# M030GAE register map
File version: 1.0
Registers are 32-bit, read-write, reset 0x0 unless marked. A register's access mark holds for its fields unless they carry their own. Offsets are from the block's base; [hi:lo] are bit positions; 'fields as' and 'values as' point back to an identical list.

## CLK — CLK Register Map
Base 0x40000200
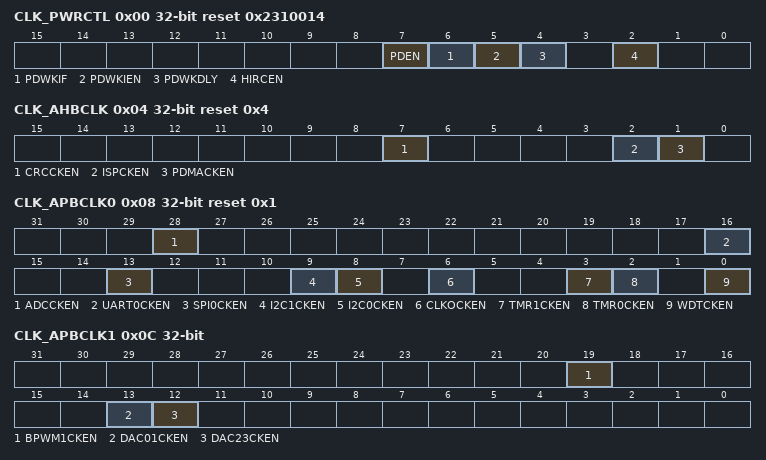
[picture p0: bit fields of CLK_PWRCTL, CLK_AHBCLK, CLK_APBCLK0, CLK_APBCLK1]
0x00 CLK_PWRCTL reset 0x2310014 — System Power-down Control Register
  [7] PDEN — System Power-down Enable (Write Protect). When this bit is set to 1, Power-down mode is enabled and chip keeps active till the CPU sleep mode is also active and then the chip enters Power-down mode. When chip wakes up from Power-down mode, this bit is auto cleared. Users need to set this bit again for next Power-down. In Power-down mode, the HIRC will be disabled in this mode, but LIRC are not controlled by Power-down mode. If user disable LIRC before entering power-down mode, this bit should be set after LIRC disabled at least 50us. The clocks of peripheral are not controlled by Power-down mode, if the peripheral clock source is from LIRC. Note: This bit is write protected. Refer to the SYS_REGLCTL register.
    0=Chip operating normally or chip in idle mode because of WFI command; 1=Chip enters Power-down mode instantly or waits CPU sleep command WFI
  [6] PDWKIF — Power-down Mode Wake-up Interrupt Status. Set by 'Power-down wake-up event', it indicates that resume from Power-down mode' The flag is set if any wake-up source is occurred. Refer Power Modes and Wake-up Sources chapter. Note 1: Write 1 to clear the bit to 0. Note 2: This bit works only if PDWKIEN (CLK_PWRCTL[5]) set to 1.
  [5] PDWKIEN — Power-down Mode Wake-up Interrupt Enable Bit (Write Protect). Note 1: The interrupt will occur when both PDWKIF and PDWKIEN are high. Note 2: This bit is write protected. Refer to the SYS_REGLCTL register.
    0=Power-down mode wake-up interrupt Disabled; 1=Power-down mode wake-up interrupt Enabled
  [4] PDWKDLY — Enable the Wake-up Delay Counter (Write Protect). When the chip wakes up from Power-down mode, the clock control will delay certain clock cycles to wait system clock stable. The delayed clock cycle is 512 clock cycles when chip works at internal high speed RC oscillator (HIRC). Note: This bit is write protected. Refer to the SYS_REGLCTL register.
    0=Clock cycles delay Disabled; 1=Clock cycles delay Enabled
  [2] HIRCEN — HIRC Enable Bit (Write Protect). Note: This bit is write protected. Refer to the SYS_REGLCTL register.
    0=Internal high speed RC oscillator (HIRC) Disabled; 1=Internal high speed RC oscillator (HIRC) Enabled
0x04 CLK_AHBCLK reset 0x4 — AHB Devices Clock Enable Control Register
  [7] CRCCKEN — CRC Generator Controller Clock Enable Bit
    0=CRC peripheral clock Disabled; 1=CRC peripheral clock Enabled
  [2] ISPCKEN — Flash ISP Controller Clock Enable Bit
    0=Flash ISP peripheral clock Disabled; 1=Flash ISP peripheral clock Enabled
  [1] PDMACKEN — PDMA Controller Clock Enable Bit
    0=PDMA peripheral clock Disabled; 1=PDMA peripheral clock Enabled
0x08 CLK_APBCLK0 reset 0x1 — APB Devices Clock Enable Control Register 0
  [28] ADCCKEN — ADC Clock Enable Bit
    0=ADC clock Disabled; 1=ADC clock Enabled
  [16] UART0CKEN — UART0 Clock Enable Bit
    0=UART0 clock Disabled; 1=UART0 clock Enabled
  [13] SPI0CKEN — SPI0 Clock Enable Bit
    0=SPI0 clock Disabled; 1=SPI0 clock Enabled
  [9] I2C1CKEN — I2C1 Clock Enable Bit
    0=I2C1 clock Disabled; 1=I2C1 clock Enabled
  [8] I2C0CKEN — I2C0 Clock Enable Bit
    0=I2C0 clock Disabled; 1=I2C0 clock Enabled
  [6] CLKOCKEN — CLKO Clock Enable Bit
    0=CLKO clock Disabled; 1=CLKO clock Enabled
  [3] TMR1CKEN — Timer1 Clock Enable Bit
    0=Timer1 clock Disabled; 1=Timer1 clock Enabled
  [2] TMR0CKEN — Timer0 Clock Enable Bit
    0=Timer0 clock Disabled; 1=Timer0 clock Enabled
  [0] WDTCKEN — Watchdog Timer Clock Enable Bit (Write Protect). Note 1: This bit is write protected. Refer to the SYS_REGLCTL register. Note 2: This bit is reset by power on reset, Watchdog reset or software chip reset.
    0=Watchdog timer clock Disabled; 1=Watchdog timer clock Enabled
0x0C CLK_APBCLK1 — APB Devices Clock Enable Control Register 1
  [19] BPWM1CKEN — BPWM1 Clock Enable Bit
    0=BPWM1 clock Disabled; 1=BPWM1 clock Enabled
  [13] DAC01CKEN — DAC01 Clock Enable Bit
    0=DAC01 clock Disabled; 1=DAC01 clock Enabled
  [12] DAC23CKEN — DAC23 Clock Enable Bit
    0=DAC23 clock Disabled; 1=DAC23 clock Enabled
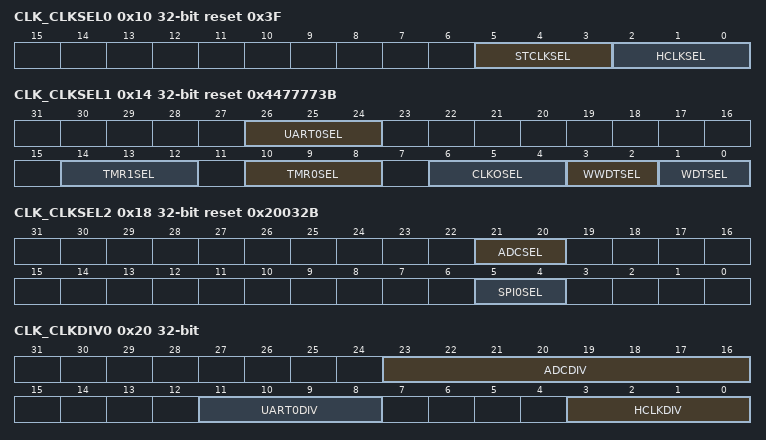
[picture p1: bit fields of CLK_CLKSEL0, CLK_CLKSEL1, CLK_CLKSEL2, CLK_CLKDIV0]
0x10 CLK_CLKSEL0 reset 0x3F — Clock Source Select Control Register 0
  [5:3] STCLKSEL — Cortex-M0 SysTick Clock Source Selection (Write Protect). Note 2: This bit is write protected. Refer to the SYS_REGLCTL register.
    3=Clock source from HCLK/2; 7=Clock source from HIRC/2
  [2:0] HCLKSEL — HCLK Clock Source Selection (Write Protect). Before clock switching, the related clock sources (both pre-select and new-select) must be turned on. Note 1: This bit is write protected. Refer to the SYS_REGLCTL register. Note 2: Reset by power on reset
    7=Clock source from HIRC
0x14 CLK_CLKSEL1 reset 0x4477773B — Clock Source Select Control Register 1
  [26:24] UART0SEL — UART0 Clock Source Selection
    3=Clock source from internal high speed RC oscillator (HIRC); 4=Clock source from PCLK0; 5=Clock source from internal low speed RC oscillator (LIRC)
  [14:12] TMR1SEL — TIMER1 Clock Source Selection
    2=Clock source from PCLK0; 3=Clock source from external clock T1 pin; 5=Clock source from internal low speed RC oscillator (LIRC); 7=Clock source from internal high speed RC oscillator (HIRC)
  [10:8] TMR0SEL — TIMER0 Clock Source Selection
    2=Clock source from PCLK0; 3=Clock source from external clock T0 pin; 5=Clock source from internal low speed RC oscillator (LIRC); 7=Clock source from internal high speed RC oscillator (HIRC)
  [6:4] CLKOSEL — Clock Divider Clock Source Selection
    2=Clock source from HCLK; 3=Clock source from internal high speed RC oscillator (HIRC); 4=Clock source from internal low speed RC oscillator (LIRC); 5=Clock source from internal high speed RC oscillator (HIRC)
  [3:2] WWDTSEL — Window Watchdog Timer Clock Source Selection (Write Protect)
    2=Clock source from HCLK/2048; 3=Clock source from internal low speed RC oscillator (LIRC)
  [1:0] WDTSEL — Watchdog Timer Clock Source Selection (Write Protect). Note1: This bit is write protected. Refer to the SYS_REGLCTL registere. Note2: This bit is force to 11 when CONFIG0[31], CONFIG0[4], CONFIG0[3] are all ones.
    values as WWDTSEL
0x18 CLK_CLKSEL2 reset 0x20032B — Clock Source Select Control Register 2
  [21:20] ADCSEL — ADC Clock Source Selection
    2=Clock source from PCLK1; 3=Clock source from internal high speed RC oscillator (HIRC) clock
  [5:4] SPI0SEL — SPI0 Clock Source Selection
    2=Clock source from PCLK1; 3=Clock source from internal high speed RC oscillator (HIRC)
0x20 CLK_CLKDIV0 — Clock Divider Number Register 0
  [23:16] ADCDIV — ADC Clock Divide Number From ADC Clock Source
  [11:8] UART0DIV — UART0 Clock Divide Number From UART0 Clock Source
  [3:0] HCLKDIV — HCLK Clock Divide Number From HCLK Clock Source
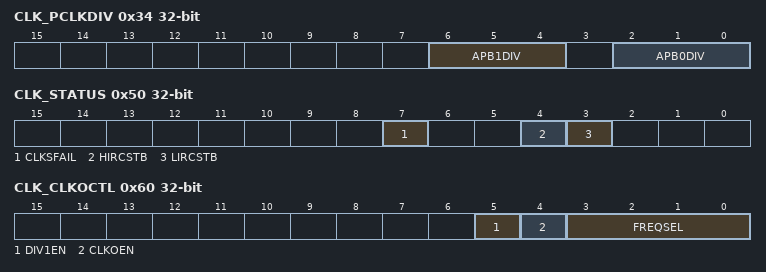
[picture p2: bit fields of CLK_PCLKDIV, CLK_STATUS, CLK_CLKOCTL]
0x34 CLK_PCLKDIV — APB Clock Divider Register
  [6:4] APB1DIV — APB1 Clock DIvider. APB1 clock can be divided from HCLK. Others: Reserved.
  [2:0] APB0DIV — APB0 Clock DIvider. APB0 clock can be divided from HCLK. Others: Reserved.
0x50 CLK_STATUS ro (reset mask 0xFFFFFF00) — Clock Status Monitor Register
  [7] CLKSFAIL — Clock Switching Fail Flag (Read Only). This bit is updated when software switches system clock source. If switch target clock is stable, this bit will be set to 0. If switch target clock is not stable, this bit will be set to 1. Note: Write 1 to clear the bit to 0.
    0=Clock switching success; 1=Clock switching failure
  [4] HIRCSTB — HIRC Clock Source Stable Flag (Read Only)
    0=Internal high speed RC oscillator (HIRC) clock is not stable or disabled; 1=Internal high speed RC oscillator (HIRC) clock is stable and enabled
  [3] LIRCSTB — LIRC Clock Source Stable Flag (Read Only)
    0=Internal low speed RC oscillator (LIRC) clock is not stable or disabled; 1=Internal low speed RC oscillator (LIRC) clock is stable and enabled
0x60 CLK_CLKOCTL — Clock Output Control Register
  [5] DIV1EN — Clock Output Divide One Enable Bit
    0=Clock Output will output clock with source frequency divided by FREQSEL; 1=Clock Output will output clock with source frequency
  [4] CLKOEN — Clock Output Enable Bit
    0=Clock Output function Disabled; 1=Clock Output function Enabled
  [3:0] FREQSEL — Clock Output Frequency Selection. The formula of output frequency is. Fin is the input clock frequency. Fout is the frequency of divider output clock. N is the 4-bit value of FREQSEL[3:0].
